# ime5_target_db register map
Vendor: Texas Instruments
Address unit: 16 bits
Registers are 32-bit, access per field, reset 0x0 unless marked. A register's access mark holds for its fields unless they carry their own. Offsets are as the file gives them; [hi:lo] are bit positions; {n}, {i} and the like mark numbered series; 'fields as' and 'values as' point back to an identical list.

## IME5 (part 3 of 3) — ipxact12_to_ccs_generated
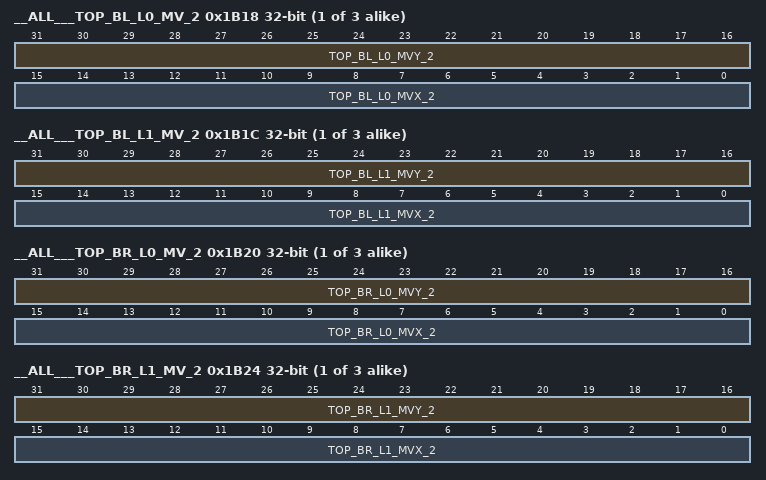
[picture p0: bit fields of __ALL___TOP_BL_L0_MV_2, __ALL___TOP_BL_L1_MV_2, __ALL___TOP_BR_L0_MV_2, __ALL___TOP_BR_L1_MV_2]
{0x1AF0+0x14*i} __ALL___TOP_BL_L0_MV_{i} rw (i=2..4)
  [31:16] TOP_BL_L0_MVY_{i}, [15:0] TOP_BL_L0_MVX_{i}
{0x1AF4+0x14*i} __ALL___TOP_BL_L1_MV_{i} rw (i=2..4)
  [31:16] TOP_BL_L1_MVY_{i}, [15:0] TOP_BL_L1_MVX_{i}
{0x1AF8+0x14*i} __ALL___TOP_BR_L0_MV_{i} rw (i=2..4)
  [31:16] TOP_BR_L0_MVY_{i}, [15:0] TOP_BR_L0_MVX_{i}
{0x1AFC+0x14*i} __ALL___TOP_BR_L1_MV_{i} rw (i=2..4)
  [31:16] TOP_BR_L1_MVY_{i}, [15:0] TOP_BR_L1_MVX_{i}
0x1B50 __ALL___TOP_MVP_INFO_POINTER ro — pointer into the circular buffer
  [1:0] TOP_MVP_INFO_POINTER
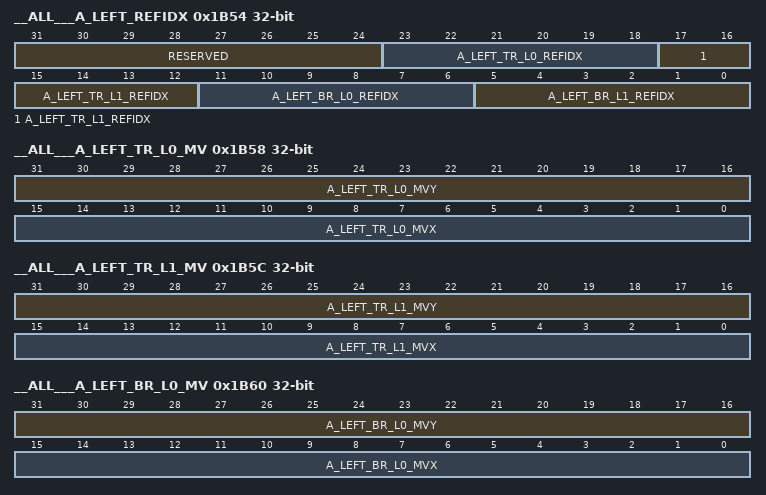
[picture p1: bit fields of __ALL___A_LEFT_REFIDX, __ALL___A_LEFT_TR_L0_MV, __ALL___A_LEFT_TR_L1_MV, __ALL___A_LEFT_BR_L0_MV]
0x1B54 __ALL___A_LEFT_REFIDX
  [31:24] RESERVED ro — A - Left MVP-Info
  [23:18] A_LEFT_TR_L0_REFIDX rw — A and B left mvp-info register act as ping pong. If A buffer stores the left macro-blocks' mvp info, then the B register stores the current macro-blocks' mvp info that will be used for the next macro-block to the right. And vice-versa.
  [17:12] A_LEFT_TR_L1_REFIDX rw — Having a separate A and B buffer could be potentially avoided. Since
  [11:6] A_LEFT_BR_L0_REFIDX rw
  [5:0] A_LEFT_BR_L1_REFIDX rw
0x1B58 __ALL___A_LEFT_TR_L0_MV rw
  [31:16] A_LEFT_TR_L0_MVY, [15:0] A_LEFT_TR_L0_MVX
0x1B5C __ALL___A_LEFT_TR_L1_MV rw
  [31:16] A_LEFT_TR_L1_MVY, [15:0] A_LEFT_TR_L1_MVX
0x1B60 __ALL___A_LEFT_BR_L0_MV rw
  [31:16] A_LEFT_BR_L0_MVY, [15:0] A_LEFT_BR_L0_MVX
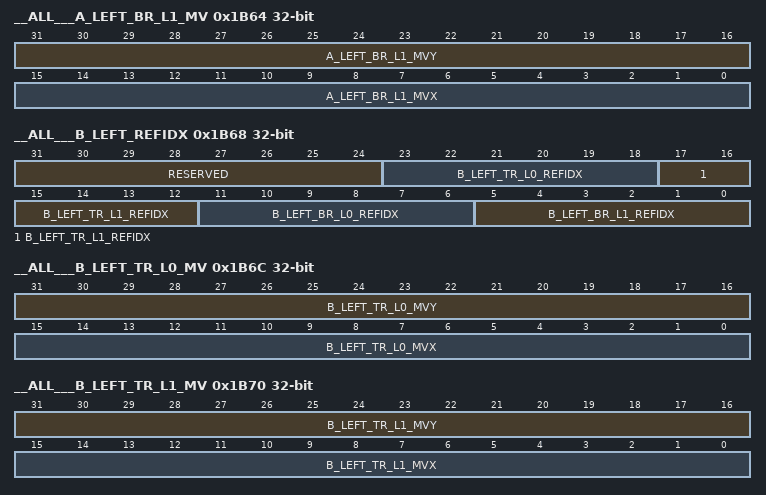
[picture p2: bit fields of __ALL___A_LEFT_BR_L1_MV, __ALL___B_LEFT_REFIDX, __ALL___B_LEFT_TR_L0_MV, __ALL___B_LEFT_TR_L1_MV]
0x1B64 __ALL___A_LEFT_BR_L1_MV rw
  [31:16] A_LEFT_BR_L1_MVY, [15:0] A_LEFT_BR_L1_MVX
0x1B68 __ALL___B_LEFT_REFIDX
  [31:24] RESERVED ro — B - Left MVP-info output
  [23:18] B_LEFT_TR_L0_REFIDX rw
  [17:12] B_LEFT_TR_L1_REFIDX rw
  [11:6] B_LEFT_BR_L0_REFIDX rw
  [5:0] B_LEFT_BR_L1_REFIDX rw
0x1B6C __ALL___B_LEFT_TR_L0_MV rw
  [31:16] B_LEFT_TR_L0_MVY, [15:0] B_LEFT_TR_L0_MVX
0x1B70 __ALL___B_LEFT_TR_L1_MV rw
  [31:16] B_LEFT_TR_L1_MVY, [15:0] B_LEFT_TR_L1_MVX
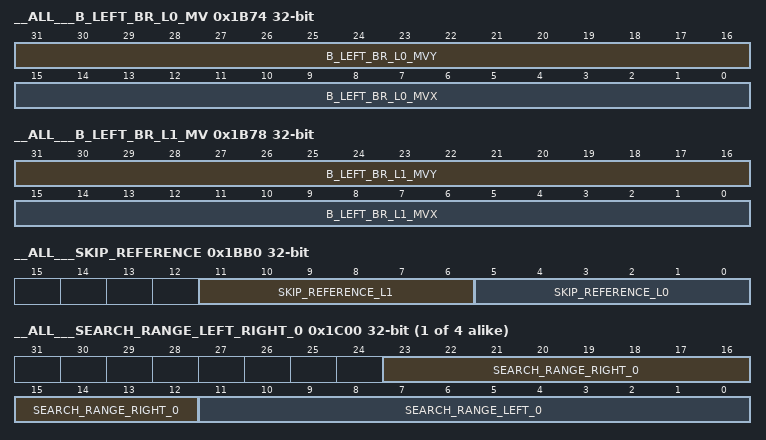
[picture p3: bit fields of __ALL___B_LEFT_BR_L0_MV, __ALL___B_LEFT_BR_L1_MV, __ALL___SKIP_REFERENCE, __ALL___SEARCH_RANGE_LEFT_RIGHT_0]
0x1B74 __ALL___B_LEFT_BR_L0_MV rw
  [31:16] B_LEFT_BR_L0_MVY, [15:0] B_LEFT_BR_L0_MVX
0x1B78 __ALL___B_LEFT_BR_L1_MV rw
  [31:16] B_LEFT_BR_L1_MVY, [15:0] B_LEFT_BR_L1_MVX
0x1B7C __ALL___LEFT_MVP_INFO_POINTER
  [0] LEFT_MVP_INFO_POINTER rw — pointer in to the ping pong buffer pointing to the current position (ping or pong).
{0x1B80+4i} __ALL___MVP_{i} rw (i=0..3)
  [31:0] MVP_{i}
0x1B90 __ALL___MVP_0_P1 rw
  [31:0] MVP_0
0x1B94 __ALL___MVP_1_p1 rw
  [31:0] MVP_1
0x1B98 __ALL___MVP_2_P1 rw
  [31:0] MVP_2
0x1B9C __ALL___MVP_3_P1 rw
  [31:0] MVP_3
0x1BA8 __ALL___SKIP_MV_L0 rw
  [31:0] SKIP_MV_L0
0x1BAC __ALL___SKIP_MV_L1 rw
  [31:0] SKIP_MV_L1
0x1BB0 __ALL___SKIP_REFERENCE
  [11:6] SKIP_REFERENCE_L1 rw, [5:0] SKIP_REFERENCE_L0 rw
{0x1C00+8i} __ALL___SEARCH_RANGE_LEFT_RIGHT_{i} (i=0..3)
  [23:12] SEARCH_RANGE_RIGHT_{i} rw, [11:0] SEARCH_RANGE_LEFT_{i} rw
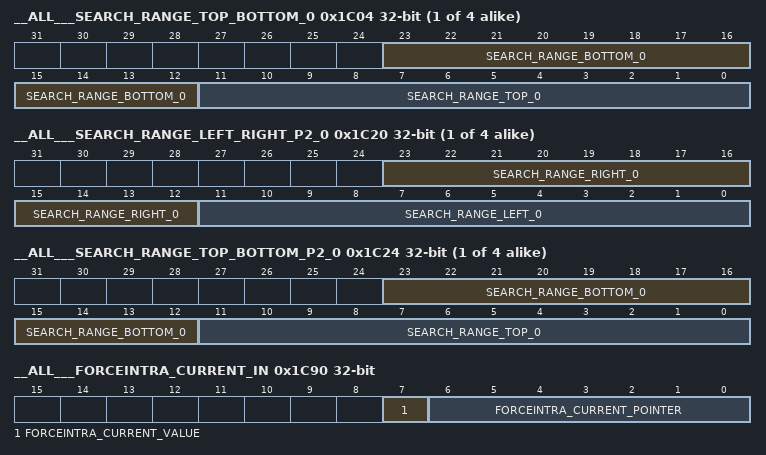
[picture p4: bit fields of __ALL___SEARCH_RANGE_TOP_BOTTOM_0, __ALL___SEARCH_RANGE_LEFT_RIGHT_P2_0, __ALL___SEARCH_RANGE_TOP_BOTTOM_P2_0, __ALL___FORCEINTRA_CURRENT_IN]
{0x1C04+8i} __ALL___SEARCH_RANGE_TOP_BOTTOM_{i} (i=0..3)
  [23:12] SEARCH_RANGE_BOTTOM_{i} rw, [11:0] SEARCH_RANGE_TOP_{i} rw
{0x1C20+8i} __ALL___SEARCH_RANGE_LEFT_RIGHT_P2_{i} (i=0..3)
  [23:12] SEARCH_RANGE_RIGHT_{i} rw, [11:0] SEARCH_RANGE_LEFT_{i} rw
{0x1C24+8i} __ALL___SEARCH_RANGE_TOP_BOTTOM_P2_{i} (i=0..3)
  [23:12] SEARCH_RANGE_BOTTOM_{i} rw, [11:0] SEARCH_RANGE_TOP_{i} rw
{0x1C80+4i} __ALL___FORCEINTRA{i} rw (i=0..3)
0x1C90 __ALL___FORCEINTRA_CURRENT_IN
  [7] FORCEINTRA_CURRENT_VALUE rw, [6:0] FORCEINTRA_CURRENT_POINTER rw
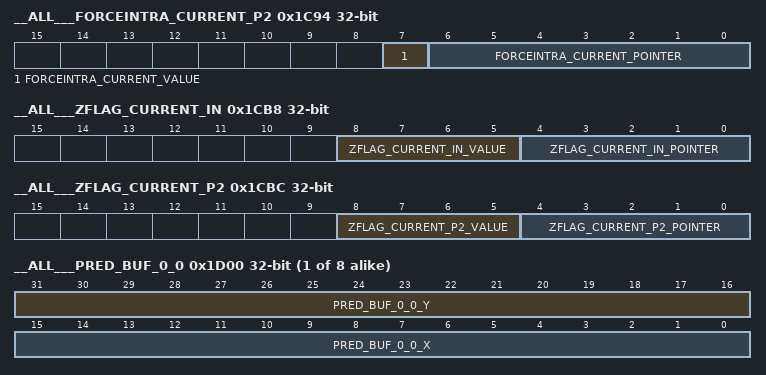
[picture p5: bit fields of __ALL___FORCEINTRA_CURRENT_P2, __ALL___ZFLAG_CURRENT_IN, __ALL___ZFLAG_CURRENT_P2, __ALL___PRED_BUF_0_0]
0x1C94 __ALL___FORCEINTRA_CURRENT_P2
  [7] FORCEINTRA_CURRENT_VALUE rw, [6:0] FORCEINTRA_CURRENT_POINTER rw
0x1C98 __ALL___ZFLAG_OUT_0 rw
  [31:0] ZFLAG_OUT_0
0x1C9C __ALL___ZFLAG_OUT_1 rw reset 0x1
  [31:0] ZFLAG_OUT_1
0x1CA0 __ALL___ZFLAG_OUT_2 rw reset 0x2
  [31:0] ZFLAG_OUT_2
0x1CA4 __ALL___ZFLAG_OUT_3 rw reset 0x3
  [31:0] ZFLAG_OUT_3
{0x1CA8+4i} __ALL___ZFLAG_IN_{i} rw (i=0..3)
  [31:0] ZFLAG_IN_{i}
0x1CB8 __ALL___ZFLAG_CURRENT_IN
  [8:5] ZFLAG_CURRENT_IN_VALUE rw — zero flags for the 4 8x8 sub-blocks in the macro-block indicating whether the motion vector is small (1) or large (0) for the corresponding 8x8 block. This is used in BSKIP motion vector calculation for future frames, to choose between non zero skip motion vector and zero motion vector as the bskip mv. For future frames, macro-block, this information is written to SL2 and then to DDR based on the motion vectors of the current macro-block. For BSKIP mv calculation of the current macro-block, this information is loaded from DDR to sl2 and is then loaded from sl2 to iME5
  [4:0] ZFLAG_CURRENT_IN_POINTER rw
0x1CBC __ALL___ZFLAG_CURRENT_P2
  [8:5] ZFLAG_CURRENT_P2_VALUE rw — zero flags for the 4 8x8 sub-blocks in the macro-block indicating whether the motion vector is small (1) or large (0) for the corresponding 8x8 block. This is used in BSKIP motion vector calculation for future frames, to choose between non zero skip motion vector and zero motion vector as the bskip mv. For future frames, macro-block, this information is written to SL2 and then to DDR based on the motion vectors of the current macro-block. For BSKIP mv calculation of the current macro-block, this information is loaded from DDR to sl2 and is then loaded from sl2 to iME5
  [4:0] ZFLAG_CURRENT_P2_POINTER rw
{0x1D00+4i} __ALL___PRED_BUF_0_{i} rw (i=0..7)
  [31:16] PRED_BUF_0_{i}_Y, [15:0] PRED_BUF_0_{i}_X
0x1D20 __ALL___PRED_BUF_1_0 rw
  [31:0] PRED_BUF_1_0 — x is lower 16, y is upper 16. Do we really have to break it into fields?
{0x1D20+4i} __ALL___PRED_BUF_1_{i} rw (i=1..7)
  [31:0] PRED_BUF_1_{i}
0x1D40 __ALL___PRED_BUF_2_0 rw
  [31:0] PRED_BUF_2_0 — x is lower 16, y is upper 16
{0x1D40+4i} __ALL___PRED_BUF_2_{i} rw (i=1..7)
  [31:0] PRED_BUF_2_{i}
0x1D60 __ALL___PRED_BUF_3_0 rw
  [31:0] PRED_BUF_3_0 — x is lower 16, y is upper 16
{0x1D60+4i} __ALL___PRED_BUF_3_{i} rw (i=1..7)
  [31:0] PRED_BUF_3_{i}
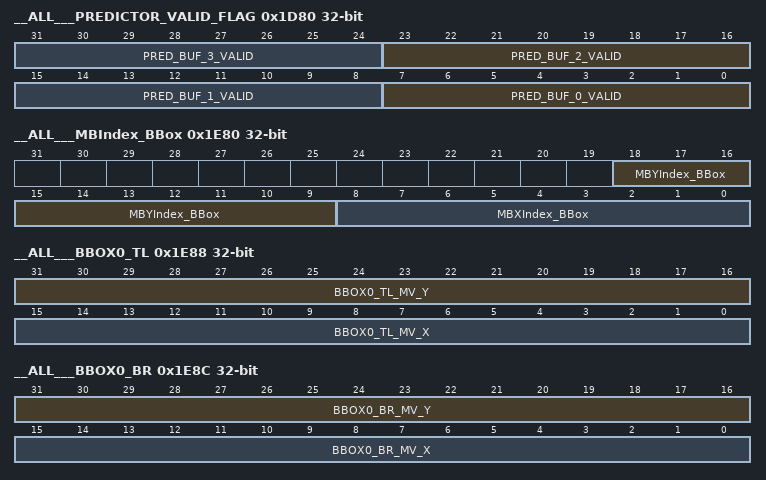
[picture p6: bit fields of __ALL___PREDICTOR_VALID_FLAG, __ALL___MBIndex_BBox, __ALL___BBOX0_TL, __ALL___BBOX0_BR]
0x1D80 __ALL___PREDICTOR_VALID_FLAG rw
  [8n+7:8n] PRED_BUF_{n}_VALID (n=0..3) — Defaults to invalid state
0x1D84 __ALL___PRED_OUT_FIFO_0_SHADOW rw
  [31:0] PRED_OUT_FIFO_0_SHADOW — again, x is lower 16, y is upper 16.
{0x1D88+0x14*i} __ALL___PRED_OUT_FIFO_{i}_0 rw (i=0..3)
  [31:0] PRED_OUT_FIFO_{i}_0
{0x1D8C+0x14*i} __ALL___PRED_OUT_FIFO_{i}_1 rw (i=0..3)
  [31:0] PRED_OUT_FIFO_{i}_1
{0x1D90+0x14*i} __ALL___PRED_OUT_FIFO_{i}_2 rw (i=0..3)
  [31:0] PRED_OUT_FIFO_{i}_2
{0x1D94+0x14*i} __ALL___PRED_OUT_FIFO_{i}_3 rw (i=0..3)
  [31:0] PRED_OUT_FIFO_{i}_3
{0x1D84+0x14*i} __ALL___PRED_OUT_FIFO_{i}_SHADOW rw (i=1..3)
  [31:0] PRED_OUT_FIFO_{i}_SHADOW
0x1E80 __ALL___MBIndex_BBox
  [18:9] MBYIndex_BBox rw — (x index is 9 bit, y index is 10 bit)
  [8:0] MBXIndex_BBox rw
0x1E88 __ALL___BBOX0_TL rw
  [31:16] BBOX0_TL_MV_Y — 31:16 is mv_y
  [15:0] BBOX0_TL_MV_X — 15:0 is mv_x
0x1E8C __ALL___BBOX0_BR rw
  [31:16] BBOX0_BR_MV_Y — 31:16 is mv_y
  [15:0] BBOX0_BR_MV_X — 15:0 is mv_x
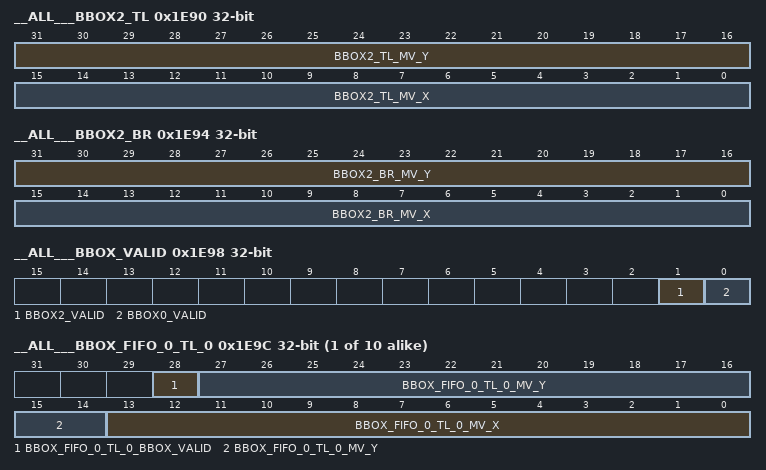
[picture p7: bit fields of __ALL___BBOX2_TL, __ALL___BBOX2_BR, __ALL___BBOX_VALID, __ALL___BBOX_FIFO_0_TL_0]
0x1E90 __ALL___BBOX2_TL rw
  [31:16] BBOX2_TL_MV_Y — 31:16 is mv_y
  [15:0] BBOX2_TL_MV_X — 15:0 is mv_x
0x1E94 __ALL___BBOX2_BR rw
  [31:16] BBOX2_BR_MV_Y — 31:16 is mv_y
  [15:0] BBOX2_BR_MV_X — 15:0 is mv_x
0x1E98 __ALL___BBOX_VALID
  [1] BBOX2_VALID rw — (in 4 pixel units)
  [0] BBOX0_VALID rw
{0x1E9C+8i} __ALL___BBOX_FIFO_0_TL_{i} (i=0..9)
  [28] BBOX_FIFO_0_TL_{i}_BBOX_VALID rw, [27:14] BBOX_FIFO_0_TL_{i}_MV_Y rw, [13:0] BBOX_FIFO_0_TL_{i}_MV_X rw
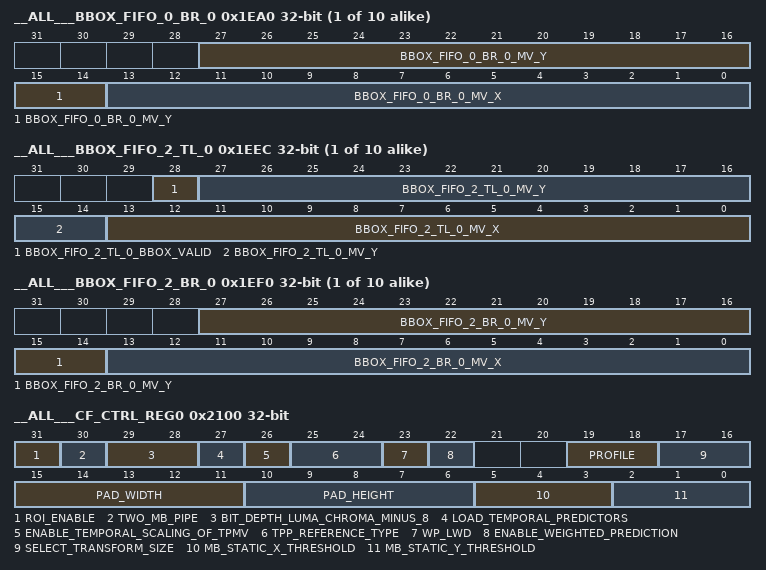
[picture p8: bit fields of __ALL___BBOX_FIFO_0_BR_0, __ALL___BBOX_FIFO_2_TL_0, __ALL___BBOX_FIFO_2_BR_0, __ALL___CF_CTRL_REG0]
{0x1EA0+8i} __ALL___BBOX_FIFO_0_BR_{i} (i=0..9)
  [27:14] BBOX_FIFO_0_BR_{i}_MV_Y rw, [13:0] BBOX_FIFO_0_BR_{i}_MV_X rw
{0x1EEC+8i} __ALL___BBOX_FIFO_2_TL_{i} (i=0..9)
  [28] BBOX_FIFO_2_TL_{i}_BBOX_VALID rw, [27:14] BBOX_FIFO_2_TL_{i}_MV_Y rw, [13:0] BBOX_FIFO_2_TL_{i}_MV_X rw
{0x1EF0+8i} __ALL___BBOX_FIFO_2_BR_{i} (i=0..9)
  [27:14] BBOX_FIFO_2_BR_{i}_MV_Y rw, [13:0] BBOX_FIFO_2_BR_{i}_MV_X rw
0x2100 __ALL___CF_CTRL_REG0
  [31] ROI_ENABLE rw — 1' : Region statistics accumulation is enabled '0' : Region statistsics accumulation is disabled
  [30] TWO_MB_PIPE rw — if '1', ME5 operates in two MB pipelined mode. If '0' ME5 operates in single MB pipelined mode.
  [29:28] BIT_DEPTH_LUMA_CHROMA_MINUS_8 rw
  [27] LOAD_TEMPORAL_PREDICTORS rw
  [26] ENABLE_TEMPORAL_SCALING_OF_TPMV rw — We may decide to scale the temporal predictor motion vectors based on temporal distance so that they represent motion per unit time. Sometimes we may want to disable temporal distance based scaling though, as the motion does not linearly change with time. for example if this reference is a long term reference... in this case, we may want to disable scaling. 0 : do not scale the temporal predictors for current frame based on temporal distance (true for all reference frames). 1 : apply scaling.
  [25:24] TPP_REFERENCE_TYPE rw — Temporal Predictor Picture's Reference Type. Used for selecting Spatial Scaling-1 type of the temporal predictor. "Type of TPP 2 Type of TPP's reference" 00 : Frame2Frame 01 : Top2Bottom 10 : Bottom2Top 11 : SameParityField
  [23] WP_LWD rw — slice level weighted prediction rounding parameter. 0 --> 6 1 --> 7 standard allows more possibilities, but we are ok with only two possibilities.
  [22] ENABLE_WEIGHTED_PREDICTION rw — 0 : disable 1 : enable
  [19:18] PROFILE rw — 00 : base 01 : simple 10 : high
  [17:16] SELECT_TRANSFORM_SIZE rw — 00 : force 8x8 transform size 01 : force 4x4 transform size 10 : enable dynamic tr8x8 update by ME 11 : no change
  [15:11] PAD_WIDTH rw — In multiples of 4 pixels. Number of horizontal padded pixels (left as well as right, each) = 4 * pad_width
  [10:6] PAD_HEIGHT rw — In multiples of 4 pixels. Number of vertical padded pixels (top as well as bottom, each) = 4 * pad_height
  [5:3] MB_STATIC_X_THRESHOLD rw — from 0 to 1.75 in steps of 0.25
  [2:0] MB_STATIC_Y_THRESHOLD rw — from 0 to 1.75 in steps of 0.25
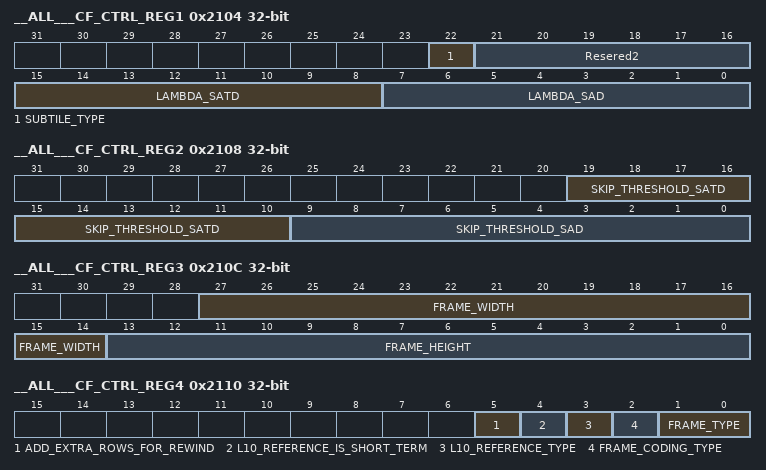
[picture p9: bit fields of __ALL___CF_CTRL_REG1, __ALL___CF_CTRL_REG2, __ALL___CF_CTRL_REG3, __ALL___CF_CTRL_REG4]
0x2104 __ALL___CF_CTRL_REG1
  [22] SUBTILE_TYPE rw — 0 : sub tile width is 4 1 : sub tile width is 8
  [21:16] Resered2 ro — Reserved
  [15:8] LAMBDA_SATD rw — separate lambda values for sad and satd are provided. icont may do following calcualtions to calculate these : lambdaSearchQ2 = qScaleQ4 * LAMBDA_SEARCH_MULT >> (LAMBDA_SEARCH_SHIFT+2); LAMBDA_SEARCH_SHIFT is a constant = 6 qScaleQ4 is a 12 bit input from IPE. Hence, lambdaSearchQ2 is a 12 bit number, which is clipped to 8 bits and used.
  [7:0] LAMBDA_SAD rw
0x2108 __ALL___CF_CTRL_REG2
  [19:10] SKIP_THRESHOLD_SATD rw — iCONT may do following calculations to calculate these : lambdaSkip = qScaleQ4 * LAMBDA_SKIP_MULT >> (LAMBDA_SEARCH_SHIFT+4); LAMBDA_SKIP_SHIFT is a constant = 6 SKIP_THRESHOLD_MIN was set to 32 in IVAHD1.0 software on iCONT SkipThreshold = max(LambdaSkip, SKIP_THRESHOLD_MIN)
  [9:0] SKIP_THRESHOLD_SAD rw
0x210C __ALL___CF_CTRL_REG3
  [27:14] FRAME_WIDTH rw — width of the current frame as well as each reference frame in pixel units
  [13:0] FRAME_HEIGHT rw — height of the current frame as well as each reference frame in pixel units
0x2110 __ALL___CF_CTRL_REG4
  [5] ADD_EXTRA_ROWS_FOR_REWIND rw — 0 : don’t add extra rows rewind (this is done when there is no rewind in the use case) 1 : when rewind is required, add extra rows in follwing data structures in SL2 : 1. temporal predictor and top spatial predictor growing windows 2. zflag input and output 3. temporal predictor output Note that this parameter does not affect the reference growing window. In this case, the extra region to take care of rewind is explicitly defined through different parameters. eg. when growing_window_method = 0, the GW_TOTAL_HEIGHT parameter can be adjusted to add 16 additional rows of pixels in the growing window. when growing_window_method = 1, GW_METH1_NUM_FETCHES_PER_ROW parameter can be adjusted to take care of rewind.
  [4] L10_REFERENCE_IS_SHORT_TERM rw
  [3] L10_REFERENCE_TYPE rw — 0 : Field 1 : Frame Used to access necessary zflags.
  [2] FRAME_CODING_TYPE rw — 0 : P frame 1 : B frame
  [1:0] FRAME_TYPE rw — 00 : frame (progressive) 01 : pure interlaced 10 : PICAFF frame 11 : PICAFF field
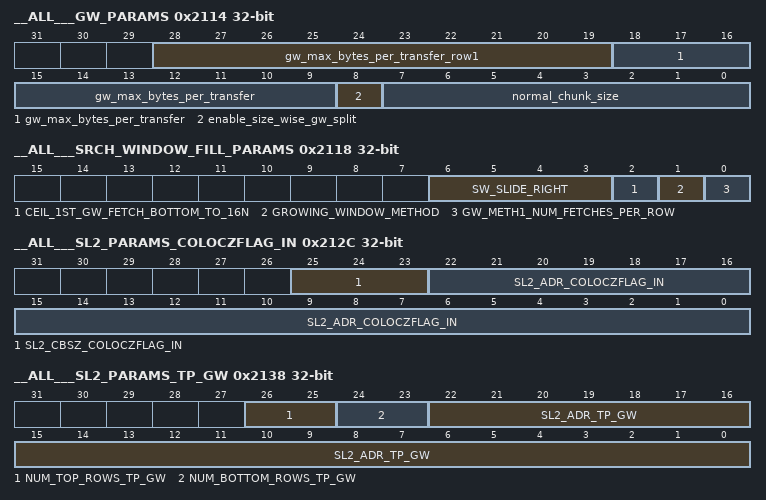
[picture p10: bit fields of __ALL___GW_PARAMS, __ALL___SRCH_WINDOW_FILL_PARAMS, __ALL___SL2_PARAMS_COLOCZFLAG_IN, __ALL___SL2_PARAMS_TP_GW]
0x2114 __ALL___GW_PARAMS
  [28:19] gw_max_bytes_per_transfer_row1 rw — 2) 3) and 4) added due to gw RTL implementation, where we split the growing window transfers into smalled sizes based on gw_max_bytes_* params. 1) is because I wanted to avoid one division operation. This can be calculated and programmed by iCONT instead of we doing it in hardware.
  [18:9] gw_max_bytes_per_transfer rw
  [8] enable_size_wise_gw_split rw
  [7:0] normal_chunk_size rw
0x2118 __ALL___SRCH_WINDOW_FILL_PARAMS
  [6:3] SW_SLIDE_RIGHT rw — Indicates the width of incremental sliding window fetches from DDR, in number of macro-blocks.
  [2] CEIL_1ST_GW_FETCH_BOTTOM_TO_16N rw — This is an optional parameter to improve DDR efficiency by reducing number of page faults. To use this feature, the growing window height should be increased to include appropriate number of extra rows.
  [1] GROWING_WINDOW_METHOD rw — 0 : growing window has extra rows of reference pixels to store data fetched by dma for future macro-block row. 1 : growing window does not have extra rows. Instead, current row fetch is broken into multiple fetches.
  [0] GW_METH1_NUM_FETCHES_PER_ROW rw — Indicates, how many sets a gw row fetch is broken into, if the growing window method is of type1. If the ME rewind needs to be supported, this should be 4. Otherwise, this should be 3. 0 : 3 1 : 4
0x211C __ALL___DDR_STRIDE
  [15:0] DDRSTRIDE rw — Width of the container in the TILER space. This parameter is used to calculate physical DDR address. Physical DDR address = x + DDR_stride * y. The logical view of the container has multiple frames mapped in 2D fashion. The container width is combined width of all the frames mapped horizontal to each other (+ may be some empty space at the end in x direction). I guess this parameter will be useful only for the frame/field data in DDR. The linear data will be mapped in non-tiled fashion and will not use this parameter.
0x2120 __ALL___DDR_ADR_COLOCZFLAG_OUT rw
  [31:0] DDR_ADR_COLOCZFLAG_OUT
0x2124 __ALL___SL2_ADR_COLOCZFLAG_OUT
  [22:0] SL2_ADR_COLOCZFLAG_OUT rw — address where colocated zero flags are written to sl2 before writing to ddr. The size of the buffer is fixed as a ping pong buffer. The width of the ping and pong buffers is equal to the number of MBs per row * 4 bits per MB -- ceiled to 128 bit boundary.
0x2128 __ALL___DDR_ADR_COLOCZFLAG_IN rw
  [31:0] DDR_ADR_COLOCZFLAG_IN — A frame can be both generator and consumer of co-located zero flags in case of hierarchical B frame sequence
0x212C __ALL___SL2_PARAMS_COLOCZFLAG_IN
  [25:23] SL2_CBSZ_COLOCZFLAG_IN rw — size of circular buffer for zflag input in terms of number of MB-rows. Note that the size of one MB row depends upon number of MBs in a row, with 4 bits per MB. The size of one MB row is ceiled to 128 bit boundary. Usually, a ping pong buffer is sufficient, so the size of the circular buffer is 2. However, in case of PicAFF when current field has a frame as L1[0] reference, the size of 4 is required. However, we dont support this case since its applicable in direct_8x8_inference flag = 0 case, which is not supported.
  [22:0] SL2_ADR_COLOCZFLAG_IN rw
0x2130 __ALL___DDR_ADR_TP_OUT rw
  [31:0] DDR_ADR_TP_OUT — These mvs may be used as temporal predictors by future frames. (Typically L0[0] or L1[0] best subpel 16x16 mvs are used for this purpose.)
0x2134 __ALL___DDR_ADR_TP_IN rw
  [31:0] DDR_ADR_TP_IN — temporal predictors are nothing but motion vectors (typically L0[0] or L1[0] best 16x16 mvs (may not be final mvs)) of one of the previously encoded frames. This may or may not be one of the reference frames of the current frame.
0x2138 __ALL___SL2_PARAMS_TP_GW
  [26:25] NUM_TOP_ROWS_TP_GW rw — 0 : only co-located row 1 : co-located and just one above row 2 : co-located and 2 above rows
  [24:23] NUM_BOTTOM_ROWS_TP_GW rw — 0 : no rows immediately below co-located row 1 : row immediately below co-located row 2 : two rows immediately below co-located row
  [22:0] SL2_ADR_TP_GW rw — SL2 address of temporal predictor growing window. Only one co-located predictor mv growing window is constructed even if there are multiple reference frames for current frame and multiple reference frames for the chosen temporal neighbor reference frame… The temporal predictor growing window maintains one extra row in SL2 to fill temporal predictors needed for the next MB row. So total number of rows = Num_Top_Rows_TP_GW + Num_Bottom_Rows_TP_GW +1
0x2140 __ALL___SL2_ADR_TOP_MVP_INFO
  [22:0] SL2_ADR_TOP_MVP_INFO rw
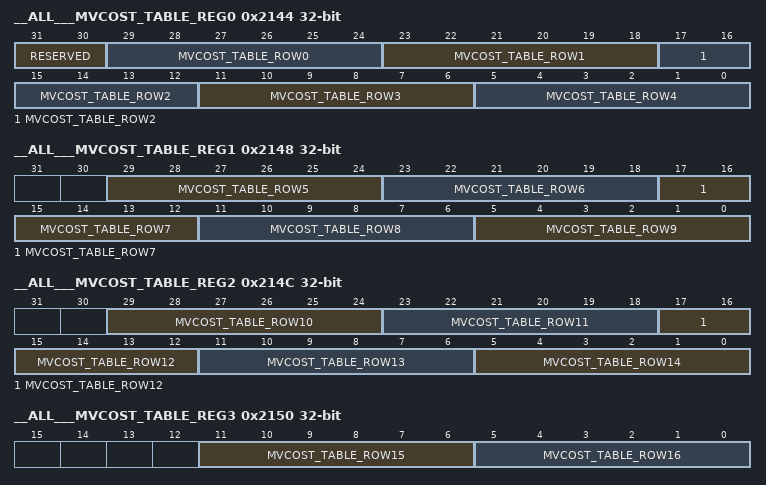
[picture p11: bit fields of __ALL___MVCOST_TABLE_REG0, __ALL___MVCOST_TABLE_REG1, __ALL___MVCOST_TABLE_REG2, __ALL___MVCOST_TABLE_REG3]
0x2144 __ALL___MVCOST_TABLE_REG0
  [31:30] RESERVED ro — The data as described above is packed into 4 32 bit registers.
  [29:24] MVCOST_TABLE_ROW0 rw — First 5 entries (0 to 4); 6 bit each
  [29-6n:24-6n] MVCOST_TABLE_ROW{n} rw (n=1..4)
0x2148 __ALL___MVCOST_TABLE_REG1
  [29:24] MVCOST_TABLE_ROW5 rw — entries 5 to 9; 6 bit each
  [59-6n:54-6n] MVCOST_TABLE_ROW{n} rw (n=6..9)
0x214C __ALL___MVCOST_TABLE_REG2
  [29:24] MVCOST_TABLE_ROW10 rw — entries 10 to 14; 6 bit each
  [89-6n:84-6n] MVCOST_TABLE_ROW{n} rw (n=11..14)
0x2150 __ALL___MVCOST_TABLE_REG3
  [11:6] MVCOST_TABLE_ROW15 rw — entries 15 and 16
  [5:0] MVCOST_TABLE_ROW16 rw
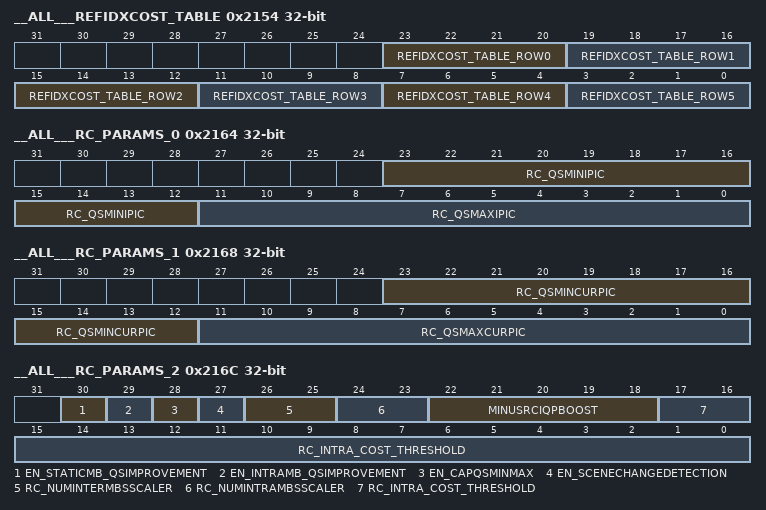
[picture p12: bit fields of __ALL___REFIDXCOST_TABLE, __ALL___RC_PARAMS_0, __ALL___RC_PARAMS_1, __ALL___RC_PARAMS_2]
0x2154 __ALL___REFIDXCOST_TABLE
  [23-4n:20-4n] REFIDXCOST_TABLE_ROW{n} rw (n=0..5)
0x2158 __ALL___MVTYPE_REG0 rw
  [31:0] MVTYPTE_REG0 — 16 4 bit entries that define the types of motion vectors being searched. Spread across two registers.
0x215C __ALL___MVTYPE_REG1 rw
  [31:0] MVTYPTE_REG1
0x2160 __ALL___SL2_ADR_FORCEINTRA
  [22:0] SL2_ADR_FORCEINTRA rw — Address of the forceintra plane
0x2164 __ALL___RC_PARAMS_0
  [23:12] RC_QSMINIPIC rw — used for rate control capQsMinMax function. This function caps the Qs between min and max Qs values. Max and min Qs values are selected either from I frame or P/B frame based on scene change detection output
  [11:0] RC_QSMAXIPIC rw — same as above
0x2168 __ALL___RC_PARAMS_1
  [23:12] RC_QSMINCURPIC rw — same as above
  [11:0] RC_QSMAXCURPIC rw — same as above
0x216C __ALL___RC_PARAMS_2
  [30] EN_STATICMB_QSIMPROVEMENT rw — used for enabling Qp improvement based on staticMB decision. This is applied to both intra and inter macro-blocks. The idea is to reduce Qp for static macro-blocks. If '1', improvement is enabled.
  [29] EN_INTRAMB_QSIMPROVEMENT rw — if '1', improvement is enabled. This improvement is applied only for intra MBs. So, done after mode decision.
  [28] EN_CAPQSMINMAX rw — If '1', improvement is enabled. This improvement is always applied irrespective of mode, when enabled.
  [27] EN_SCENECHANGEDETECTION rw — if '1', scene change detection logic is enabled for this frame.
  [26:25] RC_NUMINTERMBSSCALER rw — two bit number used to scale number of inter MBs. This is to adjust percentage of intra vs inter MBs for scene change detection.
  [24:23] RC_NUMINTRAMBSSCALER rw — two bit number used to scale number of intra MBs. This is to adjust percentage of intra vs inter MBs for scene change detection.
  [22:18] MINUSRCIQPBOOST rw — Qp delta used by MB level rate control by iME for intra MBs. 5 bit signed number.
  [17:0] RC_INTRA_COST_THRESHOLD rw — threshold used in deciding whether to update Qp for intra macro-blocks using addDelta2Quant function
0x2170 __ALL___ROI_MV_SUM_NOT_SOA
  [9:0] ROI_MV_SUM_NOT_SOA rw — if ROI_MV_SUM_NOT_SOA[i] == '1' sum of motion vector components is accumulated else sum of absolute of motion vector components is accumulated
0x2174 __ALL___MAX_ME2MC_PIPE_DELAY
  [5:0] max_ME2MC_pipe_delay rw — Required for Growing Window VIM logic
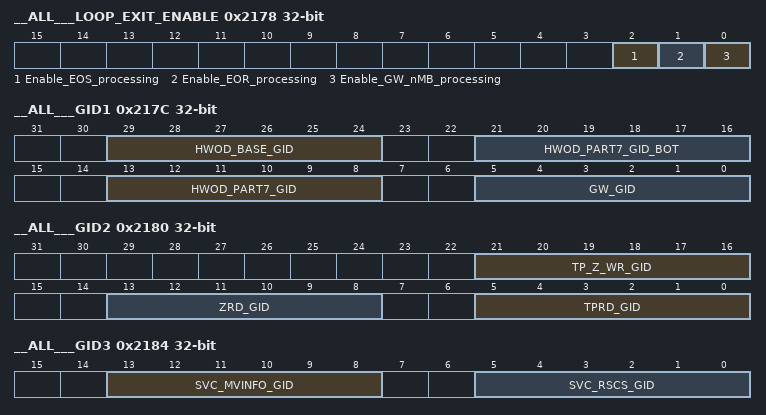
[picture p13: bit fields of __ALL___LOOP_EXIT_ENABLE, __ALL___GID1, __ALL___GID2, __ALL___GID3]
0x2178 __ALL___LOOP_EXIT_ENABLE
  [2] Enable_EOS_processing rw, [1] Enable_EOR_processing rw, [0] Enable_GW_nMB_processing rw
0x217C __ALL___GID1
  [29:24] HWOD_BASE_GID rw, [21:16] HWOD_PART7_GID_BOT rw, [13:8] HWOD_PART7_GID rw, [5:0] GW_GID rw
0x2180 __ALL___GID2
  [21:16] TP_Z_WR_GID rw, [13:8] ZRD_GID rw, [5:0] TPRD_GID rw
0x2184 __ALL___GID3
  [13:8] SVC_MVINFO_GID rw, [5:0] SVC_RSCS_GID rw
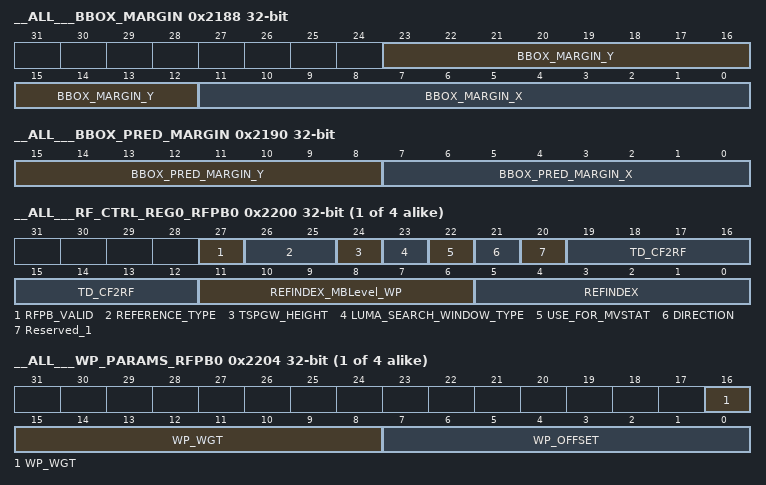
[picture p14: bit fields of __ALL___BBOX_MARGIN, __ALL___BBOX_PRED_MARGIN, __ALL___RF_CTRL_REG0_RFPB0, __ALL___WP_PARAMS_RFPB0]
0x2188 __ALL___BBOX_MARGIN
  [23:12] BBOX_MARGIN_Y rw — (in 4 pixel units)
  [11:0] BBOX_MARGIN_X rw
0x218C __ALL___BBOX_PRED_THRESHOLD rw
  [31:0] BBOX_PRED_THRESHOLD — Threshold against the area metric calculated for checking erratic predictors is compared. If the area is larger than the threshold, the predictor is considered as erratic and is eliminated from the BBox.
0x2190 __ALL___BBOX_PRED_MARGIN
  [15:8] BBOX_PRED_MARGIN_Y rw — Y margin used in area metric calculation for erratic predictors
  [7:0] BBOX_PRED_MARGIN_X rw — X margin used in area metric calculation for erratic predictors
0x2194 __ALL___NUM_HWOD_LOOK_AHEAD
  [4:0] Num_hwod_look_ahead rw — Valid values : 1 to 16
{0x2200+0x80*i} __ALL___RF_CTRL_REG0_RFPB{i} (i=0..3)
  [27] RFPB_VALID rw — 0 : RFPB is not valid 1 : RFPB is valid
  [26:25] REFERENCE_TYPE rw — Indicates the current frame type and reference frame type combination. This is required for appropriate temporal predictor spatial scaling-2. "Type of Current Frame 2 Type of Reference Frame" 00 : Frame2Frame 01 : Top2Bottom 10 : Bottom2Top 11 : SameParityField
  [24] TSPGW_HEIGHT rw — 0 : one single top-row is maintained 1 : two top rows are maintained
  [23] LUMA_SEARCH_WINDOW_TYPE rw — search window type of the luma (chroma search window when used - MC may use it - , is always a growing window) 0 : growing window 1 : hybrid window
  [22] USE_FOR_MVSTAT rw — Use this reference frame for mv stat collection required for gmv related and absolute mv sum statistics. It is software responsibility that this flag is enabled for only one of the reference frames. Only one of the reference frames can be chosen for statistics collection.
  [21] DIRECTION rw
  [20] Reserved_1 ro — store top spatial predictors from this reference frame to DDR to be used as temporal predictors by future frames. (Typically this reference frame would be L0[0] or L1[0] reference.) 0 : do not store the mvs of this reference frame to DDR 1 : store top spatial predictors from this reference to DDR. DDR address is given in the CFPB. Note that user can decide which reference frame mv is stored to DDR. However, since the iCONT populates the temporal distance parameters, iCONT and T16 programs need to be in sync. Only one of the reference frames can be chosen for storing temporal predictors. So, this flag should be '1' only in one of the RFPBs at the most.
  [19:12] TD_CF2RF rw — This distance is used for motion vector scaling. In case of long term reference, the distance can be really long. How do we support this? May be we shouldnt be scaling mvs in this case as long term reference is useful for static regions... may be adding a flag to disable scaling of mvs will help??
  [11:6] REFINDEX_MBLevel_WP rw
  [5:0] REFINDEX rw
{0x2204+0x80*i} __ALL___WP_PARAMS_RFPB{i} (i=0..3)
  [16:8] WP_WGT rw — 9 bit signed constant
  [7:0] WP_OFFSET rw — 8 bit signed constant
{0x2208+0x80*i} __ALL___WP_PARAMS_MBLevel_WP_RFPB{i} (i=0..3)
  fields as __ALL___WP_PARAMS_RFPB0
{0x220C+0x80*i} __ALL___SL2_ADR_TSP_GW_RFPB{i} (i=0..3)
  [22:0] SL2_ADR_TSP_GW rw — sl2 address for top MB-row predictor gw
{0x2210+0x80*i} __ALL___SW_DIMENSION_RFPB{i} (i=0..3)
  [23:12] SW_TOTAL_WIDTH rw — in multiples of 4 pixels
  [11:0] SW_HEIGHT rw — in multiples of 4 pixels
{0x2214+0x80*i} __ALL___GW_DIMENSION_RFPB{i} (i=0..3)
  [23:12] GW_WIDTH rw — in multiples of 4 pixels
  [11:0] GW_TOTAL_HEIGHT rw — in multiples of 4 pixels
{0x2218+0x80*i} __ALL___SEARCH_RANGE_RFPB{i} (i=0..3)
  [23:12] VSR rw
  [11:0] HSR rw — Horizontal Search Range. note that horizontal search range cannot be only derived from the sliding window width, as the sliding window width also contains extra space to take care of the pipeline delay from ME to the last user of the reference data (usually MC). Also for rewind. For 8k resolution, 11 bits are required to represent frame width/height in multiples of 4. (search range has to be multiple of 4). probably this is an overkill though, since +/-8k search range will never be valid. Also, there will be system limitations with having such a large search range.
{0x221C+0x80*i} __ALL___GMV_RFPB{i} rw (i=0..3)
  [31:0] GMV
{0x2220+0x80*i} __ALL___DDR_ADR_LUMA_RFPB{i} rw (i=0..3)
  [31:0] DDR_ADR_LUMA — DDR address of the frame (luma)
{0x2224+0x80*i} __ALL___SL2_ADR_LUMA_GW_RFPB{i} (i=0..3)
  [22:0] SL2_ADR_LUMA_GW rw — sl2 address for luma gw
{0x2228+0x80*i} __ALL___SL2_ADR_TSW_RFPB{i} (i=0..3)
  [22:0] SL2_ADR_TSW rw — sl2 address for upper sw
{0x222C+0x80*i} __ALL___SL2_ADR_BSW_RFPB{i} (i=0..3)
  [22:0] SL2_ADR_BSW rw — sl2 address for lower sw
{0x2230+0x80*i} __ALL___GMV_INT_RFPB{i} rw (i=0..3)
  [31:0] GMV — Original GMV
0x2234 __ALL___HWOD_ROW_OFFSET_RFPB0 ro (reset mask 0xFFFFC000) — Programmed by software at start of frame to : frame_width_to_fetch % sw_total_width See spec for details about frame_width_to_fetch.
0x2238 __ALL___SW_FRM_OFFSET_X_RFPB0 ro (reset mask 0xFFFF0000) — Signed number. At start of frame, it is programmed by software to : -max_val((gmv_x -hsr),0)
{0x223C+0x80*i} __ALL___TP_TSCALE_RFPB{i} (i=0..3)
  [23:0] TP_TSCALE rw — This scale factor is used for temporal scaling of temporal predictor motion vectors.
0x2334 __ALL___HWOD_ROW_OFFSET_RFPB2 ro (reset mask 0xFFFFC000) — Programmed by software at start of frame to : frame_width_to_fetch % sw_total_width See spec for details about frame_width_to_fetch.
0x2338 __ALL___SW_FRM_OFFSET_X_RFPB2 ro (reset mask 0xFFFF0000) — Signed number. At start of frame, it is programmed by software to : -max_val((gmv_x -hsr),0)
0x2500 __ALL___MBIndex_Bbox_OD
  [18:9] MBYIndex_Bbox_OD rw — (x index is 9 bit, y index is 10 bit)
  [8:0] MBXIndex_Bbox_OD rw
0x2504 __ALL___TOP_BBOX0_TL_LAST rw
  [31:16] TOP_BBOX0_TL_LAST_MV_Y — 31:16 is mv_y
  [15:0] TOP_BBOX0_TL_LAST_MV_X — 15:0 is mv_x
0x2508 __ALL___TOP_BBOX0_BR_LAST rw
  [31:16] TOP_BBOX0_BR_LAST_MV_Y — 31:16 is mv_y
  [15:0] TOP_BBOX0_BR_LAST_MV_X — 15:0 is mv_x
0x250C __ALL___BOTTOM_BBOX0_TL_LAST rw
  [31:16] BOTTOM_BBOX0_TL_LAST_MV_Y — 31:16 is mv_y
  [15:0] BOTTOM_BBOX0_TL_LAST_MV_X — 15:0 is mv_x
0x2510 __ALL___BOTTOM_BBOX0_BR_LAST rw
  [31:16] BOTTOM_BBOX0_BR_LAST_MV_Y — 31:16 is mv_y
  [15:0] BOTTOM_BBOX0_BR_LAST_MV_X — 15:0 is mv_x
0x2514 __ALL___TOP_BBOX2_TL_LAST rw
  [31:16] TOP_BBOX2_TL_LAST_MV_Y — 31:16 is mv_y
  [15:0] TOP_BBOX2_TL_LAST_MV_X — 15:0 is mv_x
0x2518 __ALL___TOP_BBOX2_BR_LAST rw
  [31:16] TOP_BBOX2_BR_LAST_MV_Y — 31:16 is mv_y
  [15:0] TOP_BBOX2_BR_LAST_MV_X — 15:0 is mv_x
0x251C __ALL___BOTTOM_BBOX2_TL_LAST rw
  [31:16] BOTTOM_BBOX2_TL_LAST_MV_Y — 31:16 is mv_y
  [15:0] BOTTOM_BBOX2_TL_LAST_MV_X — 15:0 is mv_x
0x2520 __ALL___BOTTOM_BBOX2_BR_LAST rw
  [31:16] BOTTOM_BBOX2_BR_LAST_MV_Y — 31:16 is mv_y
  [15:0] BOTTOM_BBOX2_BR_LAST_MV_X — 15:0 is mv_x
0x2524 __ALL___BBOX_NEEDED_LAST reset 0x4
  [3] BOTTOM_BBOX2_NEEDED_LAST rw — 0 TOP_BBOX0_NEEDED_LAST 1 BOTTOM_BBOX0_NEEDED_LAST
  [2] TOP_BBOX2_NEEDED_LAST rw
  [1] BOTTOM_BBOX0_NEEDED_LAST rw
  [0] TOP_BBOX0_NEEDED_LAST rw — 2 TOP_BBOX2_NEEDED_LAST 3 BOTTOM_BBOX2_NEEDED_LAST
0x2528 __ALL___GW_BOX0_BR_LAST rw
  [31:16] GW_BOX0_BR_Y_LAST — 31:16 is mv_y
  [15:0] GW_BOX0_BR_X_LAST — 15:0 is mv_x
0x252C __ALL___GW_BOX2_BR_LAST rw
  [31:16] GW_BOX2_BR_Y_LAST — 31:16 is mv_y
  [15:0] GW_BOX2_BR_X_LAST — 15:0 is mv_x
0x2530 __ALL___ROW_OFFSET_ACCUMULATOR_0 ro (reset mask 0xC000C000) — Used when RFPB0 is configured as HWOD Reset to 0 at start of frame. Reset value is also 0.
0x2534 __ALL___ROW_OFFSET_ACCUMULATOR_1 ro (reset mask 0xC000C000) — Used when RFPB2 is configured as HWOD Reset to 0 at start of frame. Reset value is also 0.
0x2538 __ALL___GW_OFFSET_Y_0 access not given reset not defined — Used when RFPB0 is configured as HWOD Signed number. At start of frame, it is programmed by software to : gw_offset_y = -max_val((gmv_y - vsr + sw_height), 0); (essentially same as gw_frm_offset_y Note that both the fields are programmed to the same value.
0x253C __ALL___GW_OFFSET_Y_1 access not given reset not defined — Used when RFPB2 is configured as HWOD Signed number. At start of frame, it is programmed by software to : gw_offset_y = -max_val((gmv_y - vsr + sw_height), 0); (essentially same as gw_frm_offset_y Note that both the fields are programmed to the same value.
0x2540 __ALL___SW_OFFSET_X_0 access not given reset not defined — Used when RFPB0 is configured as HWOD Signed number. At start of frame, sw_offset_x_reg field is programmed by software to : -max_val((gmv_x -hsr),0) The sw_next_offset_x_Reg field need not be programmed by software. For 1st MB row in frame, there is no gw2tsw transfer. So, this field is not used. From 2nd row onwards, hardware takes care of updating this field.
0x2544 __ALL___SW_OFFSET_X_1 access not given reset not defined — Used when RFPB2 is configured as HWOD Signed number. At start of frame, sw_offset_x_reg field is programmed by software to : -max_val((gmv_x -hsr),0) The sw_next_offset_x_Reg field need not be programmed by software. For 1st MB row in frame, there is no gw2tsw transfer. So, this field is not used. From 2nd row onwards, hardware takes care of updating this field.
0x2548 __ALL___GROUP_ID_D2S_CURRENT — Initialized at start of frame by sw to hwod_base_gid. Is incremented after every MB processing by BBox_VIM. The valid values go from hwod_base_gid to hwod_base_gid + num_hwod_look_ahead – 1. After the max value, the current id returns to hwod_base_gid.
  [5:0] Group_id_d2s_current rw
0x254C __ALL___DMA_IN_FLIGHT
  [15:0] DMA_IN_FLIGHT rw — Indicates status of the in-flight hybrid window dma commands. If no inflight commands are pending to complete, the bit will read ‘0’. Otherewise ‘1’.
0x2600 __ALL___VIM_GW_POSITION1
  [25:16] MB_ROW_NUM rw, [9:0] GW_EXTRA_STORAGE rw
0x2604 __ALL___VIM_GW_POSITION2_RFPB0 rw
  [31:16] GW_FETCH_BOTTOM, [15:0] GW_FETCH_RIGHT
0x2608 __ALL___VIM_GW_POSITION3_RFPB0
  [13:0] Y_DIST_SL2 rw
0x260C __ALL___VIM_GW_POSITION2_RFPB1 rw
  [31:16] GW_FETCH_BOTTOM, [15:0] GW_FETCH_RIGHT
0x2610 __ALL___VIM_GW_POSITION3_RFPB1
  [13:0] Y_DIST_SL2 rw
0x2614 __ALL___VIM_GW_POSITION2_RFPB2 rw
  [31:16] GW_FETCH_BOTTOM, [15:0] Y_DIST_SL2
0x2618 __ALL___VIM_GW_POSITION3_RFPB2
  [13:0] GW_FETCH_RIGHT rw
0x261C __ALL___VIM_GW_POSITION2_RFPB3 rw
  [31:16] GW_FETCH_BOTTOM, [15:0] Y_DIST_SL2
0x2620 __ALL___VIM_GW_POSITION3_RFPB3
  [13:0] GW_FETCH_RIGHT rw
0x2680 __ALL___Z_RD_POSITION
  [9:0] NUM_ROWS_TRANSFERRED rw
0x2684 __ALL___TP_RD_POSITION
  [9:0] NUM_ROWS_TRANSFERRED rw
0x2700 __ALL___HWOD_DMA_POSITION — On rewind, MBXIndex_hdma and MBYIndex_hdma should be initialized to rewind target MB location. Group id Offset should be initialized as below : MB_num = (num_MBs_per_row*MBYIndex_hdma) + MBXIndex_hdma; Group_id_offset = MB_num%num_hwod_look_ahead
  [15:8] MBYIndex_hdma rw, [7:0] MBXIndex_hdma rw
